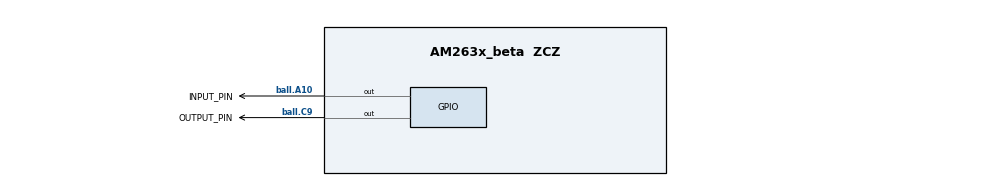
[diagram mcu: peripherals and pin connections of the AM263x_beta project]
/**
 * @cliArgs --device "AM263x_beta" --package "ZCZ" --part "AM263x" --context "r5fss0-0" --product "MCU_PLUS_SDK@07.03.01"
 * @versions {"tool":"1.12.1+2446"}
 */

/**
 * Import the modules used in this configuration.
 */
const epwm        = scripting.addModule("/drivers/epwm/epwm", {}, false);
const epwm1       = epwm.addInstance();
const epwm2       = epwm.addInstance();
const epwm3       = epwm.addInstance();
const epwm4       = epwm.addInstance();
const epwm5       = epwm.addInstance();
const epwm6       = epwm.addInstance();
const epwm7       = epwm.addInstance();
const epwm8       = epwm.addInstance();
const epwm9       = epwm.addInstance();
const epwm10      = epwm.addInstance();
const epwm11      = epwm.addInstance();
const epwm12      = epwm.addInstance();
const epwm13      = epwm.addInstance();
const epwm14      = epwm.addInstance();
const epwm15      = epwm.addInstance();
const epwm16      = epwm.addInstance();
const epwm17      = epwm.addInstance();
const epwm18      = epwm.addInstance();
const epwm19      = epwm.addInstance();
const epwm20      = epwm.addInstance();
const epwm21      = epwm.addInstance();
const epwm22      = epwm.addInstance();
const epwm23      = epwm.addInstance();
const epwm24      = epwm.addInstance();
const epwm25      = epwm.addInstance();
const epwm26      = epwm.addInstance();
const epwm27      = epwm.addInstance();
const epwm28      = epwm.addInstance();
const epwm29      = epwm.addInstance();
const epwm30      = epwm.addInstance();
const epwm31      = epwm.addInstance();
const gpio        = scripting.addModule("/drivers/gpio/gpio", {}, false);
const gpio1       = gpio.addInstance();
const gpio2       = gpio.addInstance();
const rti         = scripting.addModule("/drivers/rti/rti", {}, false);
const rti1        = rti.addInstance();
const rti2        = rti.addInstance();
const rti3        = rti.addInstance();
const uart        = scripting.addModule("/drivers/uart/uart", {}, false);
const uart1       = uart.addInstance();
const clock       = scripting.addModule("/kernel/dpl/clock");
const debug_log   = scripting.addModule("/kernel/dpl/debug_log");
const mpu_armv7   = scripting.addModule("/kernel/dpl/mpu_armv7", {}, false);
const mpu_armv71  = mpu_armv7.addInstance();
const mpu_armv72  = mpu_armv7.addInstance();
const mpu_armv73  = mpu_armv7.addInstance();
const mpu_armv74  = mpu_armv7.addInstance();
const input_xbar  = scripting.addModule("/xbar/input_xbar/input_xbar", {}, false);
const input_xbar1 = input_xbar.addInstance();

/**
 * Write custom configuration values to the imported modules.
 */
epwm1.$name        = "CONFIG_EPWM0";
epwm1.EPWM.$assign = "EPWM0";

epwm2.$name        = "CONFIG_EPWM1";
epwm2.EPWM.$assign = "EPWM1";

epwm3.$name        = "CONFIG_EPWM2";
epwm3.EPWM.$assign = "EPWM2";

epwm4.$name        = "CONFIG_EPWM3";
epwm4.EPWM.$assign = "EPWM3";

epwm5.$name        = "CONFIG_EPWM4";
epwm5.EPWM.$assign = "EPWM4";

epwm6.$name        = "CONFIG_EPWM5";
epwm6.EPWM.$assign = "EPWM5";

epwm7.$name        = "CONFIG_EPWM6";
epwm7.EPWM.$assign = "EPWM6";

epwm8.$name        = "CONFIG_EPWM7";
epwm8.EPWM.$assign = "EPWM7";

epwm9.$name        = "CONFIG_EPWM8";
epwm9.EPWM.$assign = "EPWM8";

epwm10.$name        = "CONFIG_EPWM9";
epwm10.EPWM.$assign = "EPWM9";

epwm11.$name        = "CONFIG_EPWM10";
epwm11.EPWM.$assign = "EPWM10";

epwm12.$name        = "CONFIG_EPWM11";
epwm12.EPWM.$assign = "EPWM11";

epwm13.$name        = "CONFIG_EPWM12";
epwm13.EPWM.$assign = "EPWM12";

epwm14.$name        = "CONFIG_EPWM13";
epwm14.EPWM.$assign = "EPWM13";

epwm15.$name        = "CONFIG_EPWM14";
epwm15.EPWM.$assign = "EPWM14";

epwm16.$name        = "CONFIG_EPWM15";
epwm16.EPWM.$assign = "EPWM15";

epwm17.$name        = "CONFIG_EPWM17";
epwm17.EPWM.$assign = "EPWM17";

epwm18.$name        = "CONFIG_EPWM18";
epwm18.EPWM.$assign = "EPWM18";

epwm19.$name        = "CONFIG_EPWM19";
epwm19.EPWM.$assign = "EPWM19";

epwm20.$name        = "CONFIG_EPWM20";
epwm20.EPWM.$assign = "EPWM20";

epwm21.$name        = "CONFIG_EPWM21";
epwm21.EPWM.$assign = "EPWM21";

epwm22.$name        = "CONFIG_EPWM22";
epwm22.EPWM.$assign = "EPWM22";

epwm23.$name        = "CONFIG_EPWM23";
epwm23.EPWM.$assign = "EPWM23";

epwm24.$name        = "CONFIG_EPWM24";
epwm24.EPWM.$assign = "EPWM24";

epwm25.$name        = "CONFIG_EPWM25";
epwm25.EPWM.$assign = "EPWM25";

epwm26.$name        = "CONFIG_EPWM26";
epwm26.EPWM.$assign = "EPWM26";

epwm27.$name        = "CONFIG_EPWM27";
epwm27.EPWM.$assign = "EPWM27";

epwm28.$name        = "CONFIG_EPWM28";
epwm28.EPWM.$assign = "EPWM28";

epwm29.$name        = "CONFIG_EPWM29";
epwm29.EPWM.$assign = "EPWM29";

epwm30.$name        = "CONFIG_EPWM30";
epwm30.EPWM.$assign = "EPWM30";

epwm31.$name        = "CONFIG_EPWM31";
epwm31.EPWM.$assign = "EPWM31";

gpio1.$name                = "INPUT_PIN";
gpio1.GPIO.gpioPin.$assign = "ball.A10";

gpio2.pinDir               = "OUTPUT";
gpio2.$name                = "OUTPUT_PIN";
gpio2.GPIO.gpioPin.$assign = "ball.C9";

rti1.counter0Enable = true;
rti1.compare0Enable = true;
rti1.enableIntr0    = true;
rti1.eventCallback0 = "RTI_INT_ISR";
rti1.$name          = "CONFIG_RTI1";
rti1.RTI.$assign    = "RTI1";

rti2.counter0Enable = true;
rti2.compare0Enable = true;
rti2.enableIntr0    = true;
rti2.eventCallback0 = "RTI_INT_ISR";
rti2.$name          = "CONFIG_RTI2";
rti2.RTI.$assign    = "RTI2";

rti3.counter0Enable = true;
rti3.compare0Enable = true;
rti3.enableIntr0    = true;
rti3.eventCallback0 = "RTI_INT_ISR";
rti3.$name          = "CONFIG_RTI3";
rti3.RTI.$assign    = "RTI3";

uart1.$name            = "TESTER_UART";
uart1.UART.RXD.$assign = "ball.L3";
uart1.UART.TXD.$assign = "ball.M3";

debug_log.enableUartLog            = true;
debug_log.enableCssLog             = false;
debug_log.uartLog.$name            = "CONFIG_UART0";
debug_log.uartLog.UART.$assign     = "UART0";
debug_log.uartLog.UART.RXD.$assign = "ball.A7";
debug_log.uartLog.UART.TXD.$assign = "ball.A6";

mpu_armv71.$name             = "CONFIG_MPU_REGION0";
mpu_armv71.size              = 31;
mpu_armv71.attributes        = "Device";
mpu_armv71.accessPermissions = "Supervisor RD+WR, User RD";
mpu_armv71.allowExecute      = false;

mpu_armv72.$name             = "CONFIG_MPU_REGION1";
mpu_armv72.size              = 15;
mpu_armv72.accessPermissions = "Supervisor RD+WR, User RD";

mpu_armv73.$name             = "CONFIG_MPU_REGION2";
mpu_armv73.baseAddr          = 0x80000;
mpu_armv73.size              = 15;
mpu_armv73.accessPermissions = "Supervisor RD+WR, User RD";

mpu_armv74.$name             = "CONFIG_MPU_REGION3";
mpu_armv74.accessPermissions = "Supervisor RD+WR, User RD";
mpu_armv74.baseAddr          = 0x70000000;
mpu_armv74.size              = 21;

input_xbar1.$name      = "CONFIG_INPUT_XBAR0";
input_xbar1.xbarOutput = "GPIO7";
input_xbar1.instance   = "INPUT_XBAR_5";

/**
 * Pinmux solution for unlocked pins/peripherals. This ensures that minor changes to the automatic solver in a future
 * version of the tool will not impact the pinmux you originally saw.  These lines can be completely deleted in order to
 * re-solve from scratch.
 */
epwm1.EPWM.A.$suggestSolution  = "ball.B2";
epwm1.EPWM.B.$suggestSolution  = "ball.B1";
epwm2.EPWM.A.$suggestSolution  = "ball.D3";
epwm2.EPWM.B.$suggestSolution  = "ball.D2";
epwm3.EPWM.A.$suggestSolution  = "ball.C2";
epwm3.EPWM.B.$suggestSolution  = "ball.C1";
epwm4.EPWM.A.$suggestSolution  = "ball.E2";
epwm4.EPWM.B.$suggestSolution  = "ball.E3";
epwm5.EPWM.A.$suggestSolution  = "ball.D1";
epwm5.EPWM.B.$suggestSolution  = "ball.E4";
epwm6.EPWM.A.$suggestSolution  = "ball.F2";
epwm6.EPWM.B.$suggestSolution  = "ball.G2";
epwm7.EPWM.A.$suggestSolution  = "ball.E1";
epwm7.EPWM.B.$suggestSolution  = "ball.F3";
epwm8.EPWM.A.$suggestSolution  = "ball.F4";
epwm8.EPWM.B.$suggestSolution  = "ball.F1";
epwm9.EPWM.A.$suggestSolution  = "ball.G3";
epwm9.EPWM.B.$suggestSolution  = "ball.H2";
epwm10.EPWM.A.$suggestSolution = "ball.G1";
epwm10.EPWM.B.$suggestSolution = "ball.J2";
epwm11.EPWM.A.$suggestSolution = "ball.G4";
epwm11.EPWM.B.$suggestSolution = "ball.J3";
epwm12.EPWM.A.$suggestSolution = "ball.H1";
epwm12.EPWM.B.$suggestSolution = "ball.J1";
epwm13.EPWM.A.$suggestSolution = "ball.K2";
epwm13.EPWM.B.$suggestSolution = "ball.J4";
epwm14.EPWM.A.$suggestSolution = "ball.K4";
epwm14.EPWM.B.$suggestSolution = "ball.K3";
epwm15.EPWM.A.$suggestSolution = "ball.V17";
epwm15.EPWM.B.$suggestSolution = "ball.T16";
epwm16.EPWM.A.$suggestSolution = "ball.P15";
epwm16.EPWM.B.$suggestSolution = "ball.R16";
epwm17.EPWM.A.$suggestSolution = "ball.B6";
epwm17.EPWM.B.$suggestSolution = "ball.A4";
epwm18.EPWM.A.$suggestSolution = "ball.B5";
epwm18.EPWM.B.$suggestSolution = "ball.B4";
epwm19.EPWM.A.$suggestSolution = "ball.A3";
epwm19.EPWM.B.$suggestSolution = "ball.A2";
epwm20.EPWM.A.$suggestSolution = "ball.C6";
epwm20.EPWM.B.$suggestSolution = "ball.A5";
epwm21.EPWM.A.$suggestSolution = "ball.L17";
epwm21.EPWM.B.$suggestSolution = "ball.L18";
epwm22.EPWM.A.$suggestSolution = "ball.G17";
epwm22.EPWM.B.$suggestSolution = "ball.F17";
epwm23.EPWM.A.$suggestSolution = "ball.G18";
epwm23.EPWM.B.$suggestSolution = "ball.G15";
epwm24.EPWM.A.$suggestSolution = "ball.K15";
epwm24.EPWM.B.$suggestSolution = "ball.K16";
epwm25.EPWM.A.$suggestSolution = "ball.K17";
epwm25.EPWM.B.$suggestSolution = "ball.K18";
epwm26.EPWM.A.$suggestSolution = "ball.J18";
epwm26.EPWM.B.$suggestSolution = "ball.J17";
epwm27.EPWM.A.$suggestSolution = "ball.H18";
epwm27.EPWM.B.$suggestSolution = "ball.L16";
epwm28.EPWM.A.$suggestSolution = "ball.M16";
epwm28.EPWM.B.$suggestSolution = "ball.M15";
epwm29.EPWM.A.$suggestSolution = "ball.H17";
epwm29.EPWM.B.$suggestSolution = "ball.H16";
epwm30.EPWM.A.$suggestSolution = "ball.F15";
epwm30.EPWM.B.$suggestSolution = "ball.C18";
epwm31.EPWM.A.$suggestSolution = "ball.D17";
epwm31.EPWM.B.$suggestSolution = "ball.D18";
gpio1.GPIO.$suggestSolution    = "GPIO0";
gpio2.GPIO.$suggestSolution    = "GPIO0";
uart1.UART.$suggestSolution    = "UART1";
